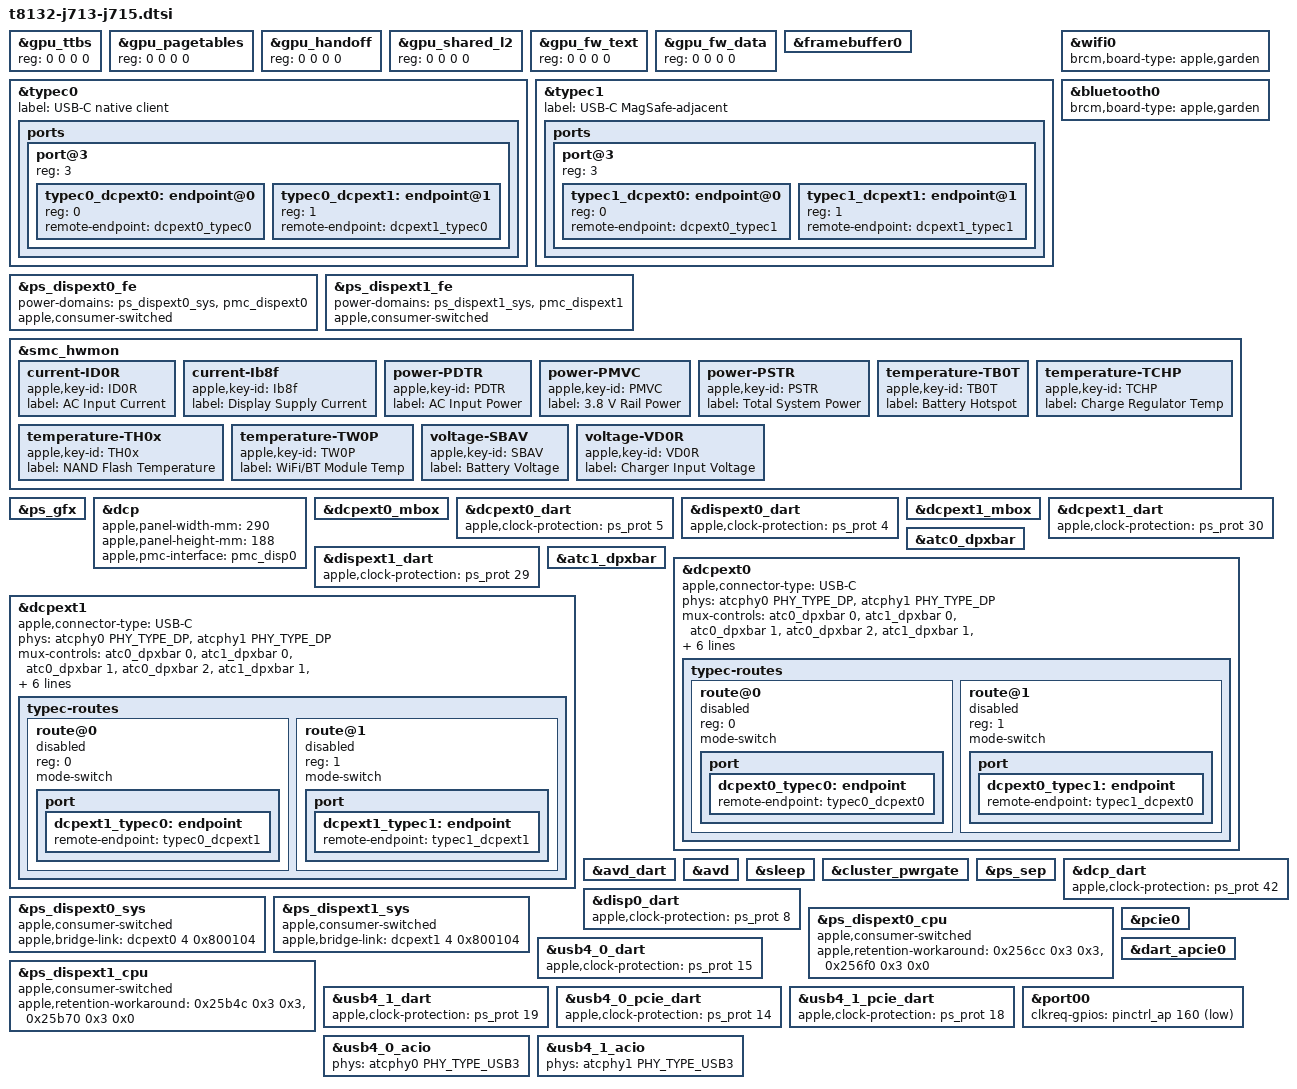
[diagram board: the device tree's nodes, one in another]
// SPDX-License-Identifier: GPL-2.0+ OR MIT
/*
 * Apple MacBook Air (13-inch and 15-inch, M4, 2025)
 *
 * The parts the J713 and J715 share. The J715 overrides the radio's
 * firmware island and the ATC PHY trims; each board adds its panel,
 * speakers and firmware names.
 *
 * Copyright The Asahi Linux Contributors
 */

#include "t8132-laptop.dtsi"
#include "t8132-j713-pmgr.dtsi"
#include <dt-bindings/phy/phy.h>

/* The J713 loader tree has these placeholders. */
&gpu_ttbs {
	reg = <0 0 0 0>;
};

&gpu_pagetables {
	reg = <0 0 0 0>;
};

&gpu_handoff {
	reg = <0 0 0 0>;
};

&gpu_shared_l2 {
	reg = <0 0 0 0>;
};

&gpu_fw_text {
	reg = <0 0 0 0>;
};

&gpu_fw_data {
	reg = <0 0 0 0>;
};

&framebuffer0 {
	/delete-property/ power-domains;
};

&typec0 {
	label = "USB-C native client";
};

&typec1 {
	label = "USB-C MagSafe-adjacent";
};

/* The radio's firmware island: the J713's here, the J715 overrides it. */
&wifi0 {
	brcm,board-type = "apple,garden";
};

&bluetooth0 {
	brcm,board-type = "apple,garden";
};

/* An external pipe's PMC enables follow its SYS state, before its FE. */
&ps_dispext0_fe {
	power-domains = <&ps_dispext0_sys>, <&pmc_dispext0>;
};

&ps_dispext1_fe {
	power-domains = <&ps_dispext1_sys>, <&pmc_dispext1>;
};

&smc_hwmon {
	current-ID0R {
		apple,key-id = "ID0R";
		label = "AC Input Current";
	};

	/* Panel and backlight supply; tracks brightness, idles when blanked. */
	current-Ib8f {
		apple,key-id = "Ib8f";
		label = "Display Supply Current";
	};

	power-PDTR {
		apple,key-id = "PDTR";
		label = "AC Input Power";
	};

	power-PMVC {
		apple,key-id = "PMVC";
		label = "3.8 V Rail Power";
	};

	power-PSTR {
		apple,key-id = "PSTR";
		label = "Total System Power";
	};

	temperature-TB0T {
		apple,key-id = "TB0T";
		label = "Battery Hotspot";
	};

	temperature-TCHP {
		apple,key-id = "TCHP";
		label = "Charge Regulator Temp";
	};

	temperature-TH0x {
		apple,key-id = "TH0x";
		label = "NAND Flash Temperature";
	};

	temperature-TW0P {
		apple,key-id = "TW0P";
		label = "WiFi/BT Module Temp";
	};

	voltage-SBAV {
		apple,key-id = "SBAV";
		label = "Battery Voltage";
	};

	voltage-VD0R {
		apple,key-id = "VD0R";
		label = "Charger Input Voltage";
	};
};

/* The GPU itself is described for every M4 Mac in t8132-gpu.dtsi. */
&ps_gfx {
	status = "okay";
};

/* The J713's full 2560x1664 panel including the notch rows, 224 ppi. */
&dcp {
	apple,panel-width-mm = <290>;
	apple,panel-height-mm = <188>;
	#address-cells = <2>;
	#size-cells = <2>;
};

/* External displays: both pipes, routed to either USB-C port. */
&dcpext0_mbox {
	status = "okay";
};

&dcpext0_dart {
	status = "okay";
};

&dispext0_dart {
	status = "okay";
};

&dcpext1_mbox {
	status = "okay";
};

&dcpext1_dart {
	status = "okay";
};

&dispext1_dart {
	status = "okay";
};

&atc0_dpxbar {
	status = "okay";
};

&atc1_dpxbar {
	status = "okay";
};

/*
 * dcpext0's Type-C routes, UFP mux selector 2 on both ATC crossbars
 * (cells 0/1/2: DP PHY, DP IN0, DP IN1). The ATC PHYs have no DP alt mode:
 * the routes are for DisplayPort tunnels, and DP alt mode is refused. The
 * routes are disabled here; the display gate enables them only for a dcpext
 * the boot loader handed over, since a USB-C port controller waits for every
 * available route.
 */
&dcpext0 {
	apple,connector-type = "USB-C";
	phys = <&atcphy0 PHY_TYPE_DP>, <&atcphy1 PHY_TYPE_DP>;
	phy-names = "typec0", "typec1";
	mux-controls = <&atc0_dpxbar 0>, <&atc1_dpxbar 0>,
		       <&atc0_dpxbar 1>, <&atc0_dpxbar 2>,
		       <&atc1_dpxbar 1>, <&atc1_dpxbar 2>;
	mux-control-names = "typec0", "typec1",
			    "typec0-dpin0", "typec0-dpin1",
			    "typec1-dpin0", "typec1-dpin1";
	apple,typec-mux-indices = <2 2>;
	apple,typec-dptx-phys = <0 1>;

	status = "okay";

	typec-routes {
		#address-cells = <1>;
		#size-cells = <0>;

		route@0 {
			reg = <0>;
			mode-switch;
			status = "disabled";

			port {
				dcpext0_typec0: endpoint {
					remote-endpoint = <&typec0_dcpext0>;
				};
			};
		};

		route@1 {
			reg = <1>;
			mode-switch;
			status = "disabled";

			port {
				dcpext0_typec1: endpoint {
					remote-endpoint = <&typec1_dcpext0>;
				};
			};
		};
	};
};

/*
 * dcpext1's Type-C routes, UFP mux selector 4 on both ATC crossbars
 * (cells 0/1/2: DP PHY, DP IN0, DP IN1). The ATC PHYs have no DP alt mode:
 * the routes are for DisplayPort tunnels, and DP alt mode is refused. The
 * routes are disabled here; the display gate enables them only for a dcpext
 * the boot loader handed over, since a USB-C port controller waits for every
 * available route.
 */
&dcpext1 {
	apple,connector-type = "USB-C";
	phys = <&atcphy0 PHY_TYPE_DP>, <&atcphy1 PHY_TYPE_DP>;
	phy-names = "typec0", "typec1";
	mux-controls = <&atc0_dpxbar 0>, <&atc1_dpxbar 0>,
		       <&atc0_dpxbar 1>, <&atc0_dpxbar 2>,
		       <&atc1_dpxbar 1>, <&atc1_dpxbar 2>;
	mux-control-names = "typec0", "typec1",
			    "typec0-dpin0", "typec0-dpin1",
			    "typec1-dpin0", "typec1-dpin1";
	apple,typec-mux-indices = <4 4>;
	apple,typec-dptx-phys = <0 1>;

	status = "okay";

	typec-routes {
		#address-cells = <1>;
		#size-cells = <0>;

		route@0 {
			reg = <0>;
			mode-switch;
			status = "disabled";

			port {
				dcpext1_typec0: endpoint {
					remote-endpoint = <&typec0_dcpext1>;
				};
			};
		};

		route@1 {
			reg = <1>;
			mode-switch;
			status = "disabled";

			port {
				dcpext1_typec1: endpoint {
					remote-endpoint = <&typec1_dcpext1>;
				};
			};
		};
	};
};

&typec0 {
	ports {
		port@3 {
			reg = <3>;
			#address-cells = <1>;
			#size-cells = <0>;

			typec0_dcpext0: endpoint@0 {
				reg = <0>;
				remote-endpoint = <&dcpext0_typec0>;
			};

			typec0_dcpext1: endpoint@1 {
				reg = <1>;
				remote-endpoint = <&dcpext1_typec0>;
			};
		};
	};
};

&typec1 {
	ports {
		port@3 {
			reg = <3>;
			#address-cells = <1>;
			#size-cells = <0>;

			typec1_dcpext0: endpoint@0 {
				reg = <0>;
				remote-endpoint = <&dcpext0_typec1>;
			};

			typec1_dcpext1: endpoint@1 {
				reg = <1>;
				remote-endpoint = <&dcpext1_typec1>;
			};
		};
	};
};

#include "t8132-j713-atcphy-tunables.dtsi"
#include "t8132-j713-usb4.dtsi"
#include "t8132-j713-usb4-tunables.dtsi"

&avd_dart {
	status = "okay";
};

&avd {
	status = "okay";
};

/*
 * Deep sleep: brought up on the J713; the J715 is the same board (same ADT
 * apart from the radio island and the ATC PHY trims).
 */
&sleep {
	status = "okay";
};

/* Deep sleep needs both CPU clusters' power gates; iBoot enables E's only. */
&cluster_pwrgate {
	status = "okay";
};

/* The ownership file above leaves the enclave domain off; the SEP needs it. */
&ps_sep {
	status = "okay";
};

/*
 * The DCP powers its display domains down while blanked
 * (appledrm.power_gate_ms): the clock protection slices of its DARTs, as the
 * ADT has them, and the internal pipe's PMC interface.
 */
&dcp_dart {
	apple,clock-protection = <&ps_prot 42>;
};

&disp0_dart {
	apple,clock-protection = <&ps_prot 8>;
};

&dcp {
	apple,pmc-interface = <&pmc_disp0>;
};

/*
 * Each external DCP powers its CPU, front-end and system domains off around
 * a deep sleep. The system domains have a bus bridge in front of their
 * block: its link words are 0x800104 past the start of the block's disp-3
 * registers (reg 4 of the external DCP).
 */
&ps_dispext0_sys {
	apple,consumer-switched;
	apple,bridge-link = <&dcpext0 4 0x800104>;
};

&ps_dispext0_fe {
	apple,consumer-switched;
};

&ps_dispext0_cpu {
	apple,consumer-switched;
	/* Power-gate retention workaround, as macOS sets it while off. */
	apple,retention-workaround = <0x256cc 0x3 0x3>, <0x256f0 0x3 0x0>;
};

&ps_dispext1_sys {
	apple,consumer-switched;
	apple,bridge-link = <&dcpext1 4 0x800104>;
};

&ps_dispext1_fe {
	apple,consumer-switched;
};

&ps_dispext1_cpu {
	apple,consumer-switched;
	/* Power-gate retention workaround, as macOS sets it while off. */
	apple,retention-workaround = <0x25b4c 0x3 0x3>, <0x25b70 0x3 0x0>;
};

/*
 * A deep sleep with a dock attached powers these off: their hosts (the ACIO
 * NHIs, the tunneled PCIe ports and the external DCPs) take them down and
 * restore them, with these clock protection slices.
 */
&usb4_0_dart {
	apple,clock-protection = <&ps_prot 15>;
};

&usb4_1_dart {
	apple,clock-protection = <&ps_prot 19>;
};

&usb4_0_pcie_dart {
	apple,clock-protection = <&ps_prot 14>;
};

&usb4_1_pcie_dart {
	apple,clock-protection = <&ps_prot 18>;
};

&dcpext0_dart {
	apple,clock-protection = <&ps_prot 5>;
};

&dispext0_dart {
	apple,clock-protection = <&ps_prot 4>;
};

&dcpext1_dart {
	apple,clock-protection = <&ps_prot 30>;
};

&dispext1_dart {
	apple,clock-protection = <&ps_prot 29>;
};

/* Native radio recovery is required before admitting system sleep. */
&pcie0 {
	status = "okay";
};

&dart_apcie0 {
	status = "okay";
};

&port00 {
	clkreq-gpios = <&pinctrl_ap 160 GPIO_ACTIVE_LOW>;
};

/* Each ACIO host powers its Type-C PHY down and up around a deep sleep with a dock. */
&usb4_0_acio {
	phys = <&atcphy0 PHY_TYPE_USB3>;
	phy-names = "cio";
};

&usb4_1_acio {
	phys = <&atcphy1 PHY_TYPE_USB3>;
	phy-names = "cio";
};
